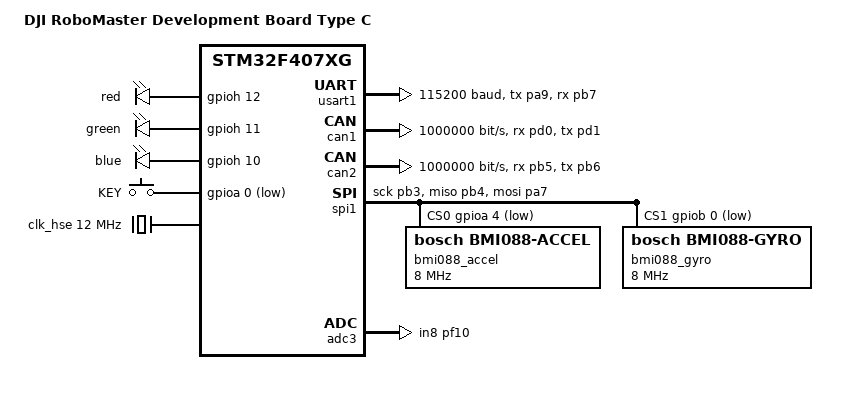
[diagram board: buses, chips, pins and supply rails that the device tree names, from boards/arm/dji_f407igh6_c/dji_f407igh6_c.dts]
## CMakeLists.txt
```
cmake_minimum_required(VERSION 3.20.0)

set(BOARD_ROOT ${CMAKE_CURRENT_SOURCE_DIR})

find_package(Zephyr REQUIRED HINTS $ENV{ZEPHYR_BASE})
project(zephyr_ascento_f407_wheel_leg C)

target_include_directories(app PRIVATE src)

target_sources(app PRIVATE
  src/main.c
  src/leds.c
  src/control_loop.c
  src/pid.c
  src/pid_balance_control.c
  src/ascento_balance.c
  src/dji_m3508.c
  src/dm4340.c
  src/motor_debug.c
  src/bmi088.c
  src/battery.c
  src/shell_commands.c
)

target_link_libraries(app PRIVATE m)
```

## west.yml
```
manifest:
  remotes:
    - name: zephyrproject-rtos
      url-base: https://github.com/zephyrproject-rtos
  projects:
    - name: zephyr
      remote: zephyrproject-rtos
      revision: v4.1.0
      import: true
  self:
    path: zephyr_ascento_f407_wheel_leg
```

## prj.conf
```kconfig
CONFIG_MAIN_STACK_SIZE=4096
CONFIG_SYSTEM_WORKQUEUE_STACK_SIZE=2048

CONFIG_GPIO=y
CONFIG_PINCTRL=y
CONFIG_SERIAL=y
CONFIG_CONSOLE=y
CONFIG_UART_CONSOLE=y
CONFIG_PRINTK=y

CONFIG_LOG=y
CONFIG_LOG_DEFAULT_LEVEL=3
CONFIG_LOG_MODE_IMMEDIATE=y

CONFIG_SHELL=y
CONFIG_KERNEL_SHELL=y
CONFIG_SHELL_STACK_SIZE=4096

CONFIG_CAN=y
CONFIG_SPI=y
CONFIG_ADC=y

CONFIG_FPU=y
CONFIG_NEWLIB_LIBC=y
CONFIG_NEWLIB_LIBC_FLOAT_PRINTF=y
CONFIG_CBPRINTF_FP_SUPPORT=y

CONFIG_THREAD_NAME=y
CONFIG_ASSERT=y

# Persistent parameter storage (direct flash read/write)
CONFIG_FLASH=y
CONFIG_FLASH_PAGE_LAYOUT=y
CONFIG_FLASH_MAP=y
CONFIG_CRC=y
```

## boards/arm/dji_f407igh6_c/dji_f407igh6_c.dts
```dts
/*
 * DJI RoboMaster Development Board Type C, STM32F407IGH6.
 *
 * The board exposes CAN1 on PD0/PD1 and CAN2 on PB5/PB6.
 * This robot uses CAN1 for DM43xx joint motors and CAN2 for DJI M3508 wheels.
 */

/dts-v1/;

#include <st/f4/stm32f407Xg.dtsi>
#include <zephyr/dt-bindings/gpio/gpio.h>
#include <zephyr/dt-bindings/pinctrl/stm32-pinctrl.h>
#include <zephyr/dt-bindings/input/input-event-codes.h>

/ {
	model = "DJI RoboMaster Development Board Type C";
	compatible = "dji,dji-f407igh6-c";

	chosen {
		zephyr,console = &usart1;
		zephyr,shell-uart = &usart1;
		zephyr,sram = &sram0;
		zephyr,flash = &flash0;
		zephyr,canbus = &can1;
	};

	aliases {
		led0 = &red_led;
		led1 = &green_led;
		led2 = &blue_led;
		sw0 = &key0;
		can-joint = &can1;
		can-dm = &can1;
		can-wheel = &can2;
		can-m3508 = &can2;
	};

	leds {
		compatible = "gpio-leds";

		red_led: red_led {
			gpios = <&gpioh 12 GPIO_ACTIVE_HIGH>;
			label = "red";
		};

		green_led: green_led {
			gpios = <&gpioh 11 GPIO_ACTIVE_HIGH>;
			label = "green";
		};

		blue_led: blue_led {
			gpios = <&gpioh 10 GPIO_ACTIVE_HIGH>;
			label = "blue";
		};
	};

	gpio_keys {
		compatible = "gpio-keys";

		key0: key_0 {
			gpios = <&gpioa 0 GPIO_ACTIVE_LOW>;
			label = "KEY";
			zephyr,code = <INPUT_KEY_0>;
		};
	};
};

&clk_hse {
	clock-frequency = <12000000>;
	status = "okay";
};

&pll {
	div-m = <12>;
	mul-n = <336>;
	div-p = <2>;
	div-q = <7>;
	clocks = <&clk_hse>;
	status = "okay";
};

&rcc {
	clocks = <&pll>;
	clock-frequency = <168000000>;
	ahb-prescaler = <1>;
	apb1-prescaler = <4>;
	apb2-prescaler = <2>;
};

&pinctrl {
	usart1_tx_pa9: usart1_tx_pa9 {
		pinmux = <STM32_PINMUX('A', 9, AF7)>;
	};

	usart1_rx_pb7: usart1_rx_pb7 {
		pinmux = <STM32_PINMUX('B', 7, AF7)>;
		bias-pull-up;
	};

	can1_rx_pd0: can1_rx_pd0 {
		pinmux = <STM32_PINMUX('D', 0, AF9)>;
		bias-pull-up;
	};

	can1_tx_pd1: can1_tx_pd1 {
		pinmux = <STM32_PINMUX('D', 1, AF9)>;
	};

	can2_rx_pb5: can2_rx_pb5 {
		pinmux = <STM32_PINMUX('B', 5, AF9)>;
		bias-pull-up;
	};

	can2_tx_pb6: can2_tx_pb6 {
		pinmux = <STM32_PINMUX('B', 6, AF9)>;
	};

	spi1_sck_pb3: spi1_sck_pb3 {
		pinmux = <STM32_PINMUX('B', 3, AF5)>;
	};

	spi1_miso_pb4: spi1_miso_pb4 {
		pinmux = <STM32_PINMUX('B', 4, AF5)>;
	};

	spi1_mosi_pa7: spi1_mosi_pa7 {
		pinmux = <STM32_PINMUX('A', 7, AF5)>;
	};

	adc3_in8_pf10: adc3_in8_pf10 {
		pinmux = <STM32_PINMUX('F', 10, ANALOG)>;
	};
};

&usart1 {
	pinctrl-0 = <&usart1_tx_pa9 &usart1_rx_pb7>;
	pinctrl-names = "default";
	current-speed = <115200>;
	status = "okay";
};

&can1 {
	pinctrl-0 = <&can1_rx_pd0 &can1_tx_pd1>;
	pinctrl-names = "default";
	bitrate = <1000000>;
	status = "okay";
};

&can2 {
	pinctrl-0 = <&can2_rx_pb5 &can2_tx_pb6>;
	pinctrl-names = "default";
	bitrate = <1000000>;
	status = "okay";
};

&spi1 {
	pinctrl-0 = <&spi1_sck_pb3 &spi1_miso_pb4 &spi1_mosi_pa7>;
	pinctrl-names = "default";
	cs-gpios = <&gpioa 4 GPIO_ACTIVE_LOW>, <&gpiob 0 GPIO_ACTIVE_LOW>;
	status = "okay";

	bmi088_accel: bmi088_accel@0 {
		compatible = "bosch,bmi088-accel";
		reg = <0>;
		spi-max-frequency = <8000000>;
	};

	bmi088_gyro: bmi088_gyro@1 {
		compatible = "bosch,bmi088-gyro";
		reg = <1>;
		spi-max-frequency = <8000000>;
	};
};

&adc3 {
	compatible = "st,stm32f4-adc", "st,stm32-adc";
	pinctrl-0 = <&adc3_in8_pf10>;
	pinctrl-names = "default";
	st,adc-prescaler = <2>;
	status = "okay";
};

/* Last 128 KB sector for NVS parameter storage. */
&flash0 {
	partitions {
		compatible = "fixed-partitions";
		#address-cells = <1>;
		#size-cells = <1>;

		storage_partition: partition@e0000 {
			label = "storage";
			reg = <0x0e0000 0x20000>;
		};
	};
};
```

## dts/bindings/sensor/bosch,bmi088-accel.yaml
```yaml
description: Bosch BMI088 accelerometer chip-select used by the application

compatible: "bosch,bmi088-accel"

include: spi-device.yaml
```

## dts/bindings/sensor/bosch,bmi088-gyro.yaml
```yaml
description: Bosch BMI088 gyroscope chip-select used by the application

compatible: "bosch,bmi088-gyro"

include: spi-device.yaml
```

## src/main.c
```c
/**
 * @file main.c
 * @brief Ascento 式双轮腿机器人 —— 系统入口与初始化
 *
 * 基于 Zephyr RTOS 的 STM32F407 双轮腿自平衡机器人主程序。
 *
 * 【硬件平台】
 *   - MCU: STM32F407 (DJI RoboMaster 开发板 C 型)
 *   - IMU: BMI088（SPI 接口，测量俯仰/横滚/偏航角及角速度）
 *   - 轮毂电机: DJI M3508 ×2（经 VESC 驱动器，CAN2 总线）
 *   - 关节电机: DM4340 ×2（髋关节直驱，CAN1 总线）
 *   - LED: 红/绿/蓝三色指示灯，用于状态反馈
 *
 * 【软件架构】
 *   - 主线程：外设初始化、LED 状态指示、500ms 周期日志输出
 *   - 控制线程：200Hz 实时平衡控制（见 control_loop.c）
 *
 * 【CAN 总线布局】
 *   - CAN1（joint）: DM4340 关节电机
 *   - CAN2（wheel）: DJI M3508 轮毂电机（VESC 协议）
 */

#include <errno.h>
#include <stdbool.h>
#include <stdint.h>

#include <zephyr/device.h>
#include <zephyr/devicetree.h>
#include <zephyr/drivers/can.h>
#include <zephyr/drivers/gpio.h>
#include <zephyr/kernel.h>
#include <zephyr/logging/log.h>
#include <zephyr/sys/util.h>

#include "app_config.h"
#include "battery.h"
#include "bmi088.h"
#include "control.h"
#include "control_loop.h"
#include "dji_m3508.h"
#include "dm4340.h"
#include "leds.h"
#include "motor_debug.h"

LOG_MODULE_REGISTER(app, LOG_LEVEL_INF);

/* ========== 设备树 CAN 节点别名 ========== */
#define WHEEL_CAN_NODE DT_ALIAS(can_wheel)
#define JOINT_CAN_NODE DT_ALIAS(can_joint)

/* ========== CAN 设备句柄 ========== */
static const struct device *wheel_can = DEVICE_DT_GET(WHEEL_CAN_NODE);
static const struct device *joint_can = DEVICE_DT_GET(JOINT_CAN_NODE);

/* ========== 电机和传感器全局对象 ========== */
static dji_m3508_bus_t dji_bus;
static dm4340_bus_t dm_bus;
static bmi088_t imu;

/* ========== 硬件初始化辅助函数 ========== */

/** @brief 初始化并启动指定 CAN 总线 */
static int prepare_can(const struct device *can, const char *name)
{
	if (!device_is_ready(can)) {
		LOG_ERR("%s is not ready", name);
		return -ENODEV;
	}

	int ret = can_set_bitrate(can, APP_CAN_BITRATE);
	if (ret != 0 && ret != -ENOTSUP) {
		LOG_WRN("%s bitrate set returned %d, using devicetree bitrate",
			name, ret);
	}

	ret = can_start(can);
	if (ret != 0 && ret != -EALREADY) {
		LOG_ERR("%s start failed: %d", name, ret);
		return ret;
	}

	LOG_INF("%s started at %u bps", name, APP_CAN_BITRATE);
	return 0;
}

/** @brief 检查是否有至少一台 DM4340 关节电机在线 */
static bool dm_any_online(void)
{
	for (uint8_t i = 1; i <= DM4340_MAX_ID; i++) {
		dm4340_feedback_t fb;
		if (dm4340_get(&dm_bus, i, &fb)) {
			return true;
		}
	}
	return false;
}

/* ========== 主函数 ========== */

int main(void)
{
	LOG_INF("DJI F407 Ascento wheel-leg Zephyr app boot");

	/* ===== 阶段 1：硬件外设初始化 ===== */
	leds_init();

	/* CAN 总线初始化 */
	if (prepare_can(joint_can, "CAN joint DM43xx") != 0) {
		LOG_ERR("joint CAN is required");
	}
	if (joint_can != wheel_can) {
		if (prepare_can(wheel_can, "CAN wheel VESC") != 0) {
			LOG_ERR("wheel CAN is required");
		}
	}

	/* 电机驱动初始化 */
	const uint8_t wheel_ids[] = { APP_WHEEL_LEFT_ID, APP_WHEEL_RIGHT_ID };
	(void)dji_m3508_init(&dji_bus, wheel_can, wheel_ids,
			     ARRAY_SIZE(wheel_ids));
	(void)dm4340_init(&dm_bus, joint_can, APP_DM_LEFT_FEEDBACK_ID,
			  APP_DM_RIGHT_FEEDBACK_ID);
	motor_debug_init(&dji_bus, &dm_bus);
	(void)dm4340_enable(&dm_bus, APP_DM_LEFT_ID);
	(void)dm4340_enable(&dm_bus, APP_DM_RIGHT_ID);

	/* 传感器初始化 */
	if (bmi088_init(&imu) != 0) {
		LOG_ERR("BMI088 init failed; balance output will stay disabled");
	}
	(void)battery_init();

	/* ===== 阶段 2：启动实时控制线程（200Hz） ===== */
	control_loop_start(&dji_bus, &dm_bus, &imu);

	/* ===== 阶段 3：主线程监控循环（500ms） ===== */
	bool heartbeat = false;
	while (true) {
		heartbeat = !heartbeat;

		control_status_t status;
		control_get_status(&status);

		const battery_sample_t battery = battery_read();

		/* LED 状态指示 */
		led_set_red(!dm_any_online() || status.faulted ||
			    !status.wheels_enabled);
		led_set_blue(battery.valid &&
			     battery.voltage_v > APP_BATTERY_LED_THRESHOLD_V);

		/* 周期日志输出 */
		if (battery.valid) {
			LOG_INF("pitch %.2f roll %.2f yaw %.1f gy %.1f gz %.1f current %d/%d "
				"height %d batt %.2f V",
				(double)status.pitch_deg,
				(double)status.roll_deg,
				(double)status.yaw_deg,
				(double)last_imu_sample.gy_dps,
				(double)last_imu_sample.gz_dps,
				status.left_wheel_current,
				status.right_wheel_current, status.height,
				(double)battery.voltage_v);
		} else {
			LOG_INF("pitch %.2f roll %.2f yaw %.1f gy %.1f gz %.1f current %d/%d "
				"height %d",
				(double)status.pitch_deg,
				(double)status.roll_deg,
				(double)status.yaw_deg,
				(double)last_imu_sample.gy_dps,
				(double)last_imu_sample.gz_dps,
				status.left_wheel_current,
				status.right_wheel_current, status.height);
		}

		k_sleep(K_MSEC(500));
	}
}
```

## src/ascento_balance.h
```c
/**
 * @file ascento_balance.h
 * @brief Ascento 风格轮腿机器人的模型化平衡控制器
 *
 * 本文件实现了基于物理模型的平衡控制器，核心思路源自 Ascento 机器人。
 * 控制器使用 LQR（线性二次调节器）方法，基于机器人的物理参数
 * （质量、惯量、轮半径、腿长等）计算最优反馈增益。
 *
 * 工作原理：
 *   1. 将机器人建模为倒立摆 + 轮子系统（5 个状态变量）
 *   2. 根据当前腿部长度动态计算 LQR 增益（增益随腿长变化）
 *   3. 增益通过多项式拟合（c0, c1, c2, c3）预计算，运行时查表
 *   4. 输出轮子扭矩指令，实现自平衡 + 前进/转向控制
 *   5. 包含静摩擦补偿、故障保护、偏航同步等功能
 *
 * 参数存储：
 *   - 默认参数通过 #define 宏定义（编译时确定）
 *   - 运行时可通过 NVS（非易失性存储）持久化自定义参数
 *   - ascento_balance_save_params() / reset_params() 管理持久化
 */

#pragma once

#include <stdbool.h>
#include <stdint.h>

#include "bmi088.h"   /* IMU 传感器数据类型 */
#include "dji_m3508.h" /* DJI M3508 电机数据类型 */

/**
 * @brief Ascento 平衡控制器参数结构体
 *
 * 包含机器人的物理参数、LQR 增益、运行时可调参数等。
 * 物理参数在初始化时设定，运行时通常不变；
 * LQR 增益和保护阈值可在运行时调整。
 */
typedef struct {
	bool calibrated; /**< 是否已完成校准（true = 参数有效） */

	/* ========== 机器人物理参数（几何与质量） ========== */

	float wheel_radius_m;    /**< 轮子半径，单位：米（m） */
	float wheel_base_m;      /**< 左右轮距（轮距），单位：米（m） */
	float total_mass_kg;     /**< 机器人总质量，单位：千克（kg） */
	float body_com_height_m; /**< 质心高度（从轮轴到质心的距离），单位：米（m） */
	float body_com_forward_offset_m; /**< 质心前后偏移（正=前倾方向），单位：米（m） */

	/* ========== 转动惯量参数 ========== */

	float body_pitch_inertia_kg_m2; /**< 机体绕俯仰轴的转动惯量，单位：kg*m^2 */
	float wheel_inertia_kg_m2;      /**< 轮子绕转轴的转动惯量，单位：kg*m^2 */

	/* ========== 电机电流到扭矩的转换系数 ========== */

	float current_ma_to_wheel_torque_nm;           /**< 默认电流-扭矩转换系数，单位：N*m/mA */
	float left_current_ma_to_wheel_torque_nm;  /**< 左轮专用电流-扭矩系数（补偿个体差异），单位：N*m/mA */
	float right_current_ma_to_wheel_torque_nm; /**< 右轮专用电流-扭矩系数（补偿个体差异），单位：N*m/mA */

	/* ========== 腿部几何参数（关节角度 <-> 腿长映射） ========== */

	float leg_length_min_m;     /**< 腿部最短长度，单位：米（m） */
	float leg_length_max_m;     /**< 腿部最长长度，单位：米（m） */
	float leg_length_default_m; /**< 腿部默认长度（初始站立高度），单位：米（m） */

	/* 关节角度与腿长的对应关系（用于关节角 -> 腿长的线性映射） */
	float left_joint_at_min_leg_rad;  /**< 左腿在最短腿长时的关节角度，单位：弧度（rad） */
	float left_joint_at_max_leg_rad;  /**< 左腿在最长腿长时的关节角度，单位：弧度（rad） */
	float right_joint_at_min_leg_rad; /**< 右腿在最短腿长时的关节角度，单位：弧度（rad） */
	float right_joint_at_max_leg_rad; /**< 右腿在最长腿长时的关节角度，单位：弧度（rad） */

	/* ========== LQR 状态反馈增益（固定部分） ========== */

	float k_pitch;     /**< 俯仰角反馈增益（平衡主回路），单位：N*m/rad */
	float k_pitch_rate; /**< 俯仰角速度反馈增益（阻尼），单位：N*m/(rad/s) */
	float k_position;  /**< 位置反馈增益（防止位置漂移），单位：N*m/m */
	float k_velocity;  /**< 速度反馈增益（速度阻尼），单位：N*m/(m/s) */
	float k_yaw_rate;  /**< 偏航角速度反馈增益（转向阻尼），单位：N*m/(rad/s) */
	float k_roll_to_leg_m_per_rad; /**< 横滚角到腿部差动的映射系数，单位：m/rad */

	/* ========== 运行时可调参数（可从 #define 默认值覆盖） ========== */

	float theta_eq_rad; /**< 平衡点俯仰角偏移（站立时的"零点"），单位：弧度（rad） */

	/* 以下 gain_c*_a/b/c 为腿部长度 -> LQR 增益的多项式拟合系数 */
	/* 用于动态计算：gain = a * leg_len^2 + b * leg_len + c */
	float gain_c0_a, gain_c0_b, gain_c0_c;  /**< 增益 c0 的多项式系数（遗留/Flash 兼容） */
	float gain_c1_a, gain_c1_b, gain_c1_c;  /**< 增益 c1 的多项式系数（遗留/Flash 兼容） */
	float gain_c2;                           /**< 增益 c2 的常数值（遗留/Flash 兼容） */
	float gain_c3_a, gain_c3_b, gain_c3_c;  /**< 增益 c3 的多项式系数（遗留/Flash 兼容） */

	/* ========== 静摩擦补偿参数 ========== */

	float stiction_current_ma;  /**< 最大静摩擦补偿电流，单位：毫安（mA） */
	float stiction_start_deg;   /**< 开始施加静摩擦补偿的角度阈值，单位：度（deg） */
	float stiction_full_deg;    /**< 施加满静摩擦补偿的角度阈值，单位：度（deg） */

	/* ========== 保护与限幅参数 ========== */

	int16_t current_limit_ma;   /**< 轮子最大输出电流限幅，单位：毫安（mA） */
	float current_scale;        /**< 电流输出缩放系数（0.0~1.0，用于降功率运行） */
	float fault_deg;            /**< 触发故障保护的倾角阈值，单位：度（deg） */
	float recover_deg;          /**< 从故障状态恢复的角度阈值（需低于 fault_deg），单位：度（deg） */

	/* ========== 偏航同步参数 ========== */

	float wheel_sync_gain_ma;          /**< 左右轮差速同步增益，单位：mA/(rad/s) */
	float wheel_sync_current_limit_ma; /**< 差速同步最大电流限幅，单位：毫安（mA） */
} ascento_balance_params_t;

/**
 * @brief Ascento 平衡控制器输入结构体
 *
 * 每个控制周期由调用方填充，包含传感器反馈和运动目标。
 */
typedef struct {
	bool enable_request;     /**< 控制器使能请求（false 时输出为零） */
	bool wheel_feedback_ok;  /**< 轮子电机反馈是否有效（通信正常） */
	float dt_s;              /**< 本控制周期的时间步长，单位：秒（s） */

	/* 运动目标 */
	float target_forward_speed_mps; /**< 目标前进速度，单位：米/秒（m/s），正值=前进 */
	float target_yaw_rate_rad_s;    /**< 目标偏航角速度，单位：弧度/秒（rad/s），正值=右转 */
	float target_pitch_rad;         /**< 目标俯仰角（通常为零，用于特殊姿态），单位：弧度（rad） */

	/* 关节反馈（来自腿部关节电机编码器） */
	float left_joint_position_rad;  /**< 左腿关节当前角度，单位：弧度（rad） */
	float right_joint_position_rad; /**< 右腿关节当前角度，单位：弧度（rad） */
	float left_joint_velocity_rad_s;  /**< 左腿关节角速度，单位：弧度/秒（rad/s） */
	float right_joint_velocity_rad_s; /**< 右腿关节角速度，单位：弧度/秒（rad/s） */

	/* 传感器反馈 */
	bmi088_sample_t imu;         /**< IMU 采样数据（加速度、角速度、姿态角） */
	dji_m3508_motor_t left_wheel;  /**< 左轮电机反馈（电流、角度、速度） */
	dji_m3508_motor_t right_wheel; /**< 右轮电机反馈（电流、角度、速度） */
} ascento_balance_input_t;

/**
 * @brief Ascento 平衡控制器输出结构体
 *
 * 每个控制周期由 ascento_balance_update() 填充，包含电机指令和内部状态。
 */
typedef struct {
	bool active;       /**< 控制器是否处于活跃状态（已使能且未故障） */
	bool params_ready; /**< 参数是否已就绪（已加载有效参数） */
	bool faulted;      /**< 是否处于故障保护状态 */

	/* 电机输出指令 */
	int16_t left_wheel_current;  /**< 左轮目标电流，单位：毫安（mA） */
	int16_t right_wheel_current; /**< 右轮目标电流，单位：毫安（mA） */
	float left_joint_position_rad;  /**< 左腿关节目标角度，单位：弧度（rad） */
	float right_joint_position_rad; /**< 右腿关节目标角度，单位：弧度（rad） */
	float joint_velocity_limit_rad_s; /**< 关节角速度限幅，单位：弧度/秒（rad/s） */

	/* 内部计算中间量（用于调试和监控） */
	float body_position_m;   /**< 机体估计位置（轮子编码器积分），单位：米（m） */
	float body_velocity_mps; /**< 机体估计速度（编码器微分 + 滤波），单位：米/秒（m/s） */
	float pitch_rad;         /**< 机体俯仰角（IMU 融合后），单位：弧度（rad） */
	float pitch_rate_rad_s;  /**< 机体俯仰角速度（陀螺仪），单位：弧度/秒（rad/s） */
	float balance_torque_nm; /**< 平衡控制计算的总扭矩，单位：牛顿米（N*m） */
	float yaw_torque_nm;     /**< 偏航控制计算的差动扭矩，单位：牛顿米（N*m） */
} ascento_balance_output_t;

/**
 * @brief Ascento 平衡控制器内部状态结构体
 *
 * 保存控制器的持久化运行状态（跨控制周期保持）。
 * 由 ascento_balance_init() 初始化，ascento_balance_update() 更新。
 */
typedef struct {
	bool initialized;  /**< 控制器是否已初始化 */
	bool faulted;      /**< 是否处于故障保护状态 */
	int recover_ticks; /**< 故障恢复倒计时（tick 数，降到零后尝试恢复平衡） */

	float body_position_m;        /**< 机体累计位移估计，单位：米（m） */
	float wheel_position_zero_m;  /**< 轮子位置零点偏移（用于位置估计归零），单位：米（m） */
	float body_velocity_lpf_mps;  /**< 机体速度的低通滤波值，单位：米/秒（m/s） */
	float yaw_rate_lpf_rad_s;     /**< 偏航角速度的低通滤波值，单位：弧度/秒（rad/s） */
	float pitch_rate_lpf_rad_s;   /**< 俯仰角速度的低通滤波值，单位：弧度/秒（rad/s） */
} ascento_balance_state_t;

/**
 * @brief 默认参数指针（指向编译时定义的默认参数表）
 *
 * 可用于在 NVS 参数损坏时恢复出厂默认值。
 */
extern const ascento_balance_params_t *ascento_balance_default_params;

/**
 * @brief 获取当前平衡控制器参数
 * @param[out] params 指向参数结构体的指针，函数将填充当前参数值
 */
void ascento_balance_get_params(ascento_balance_params_t *params);

/**
 * @brief 设置平衡控制器参数
 * @param[in] params 指向新参数结构体的指针
 *
 * 运行时动态更新参数（不持久化到 Flash）。
 */
void ascento_balance_set_params(const ascento_balance_params_t *params);

/**
 * @brief 将当前参数持久化保存到 NVS（Flash）
 * @return 0 成功，非零失败
 */
int ascento_balance_save_params(void);

/**
 * @brief 将参数重置为出厂默认值
 * @return 0 成功，非零失败
 *
 * 从 NVS 中擦除自定义参数，恢复为 #define 编译时默认值。
 */
int ascento_balance_reset_params(void);

/**
 * @brief 初始化平衡控制器的 NVS 参数存储
 * @return 0 成功，非零失败
 *
 * 从 NVS 加载已保存的参数；若 NVS 为空则使用默认值。
 * 应在系统启动时调用一次。
 */
int ascento_balance_settings_init(void);

/**
 * @brief 初始化平衡控制器状态
 * @param[out] state 指向控制器状态结构体的指针
 *
 * 清零所有内部状态，设置 initialized 标志。
 */
void ascento_balance_init(ascento_balance_state_t *state);

/**
 * @brief 重置平衡控制器状态
 * @param[out] state 指向控制器状态结构体的指针
 *
 * 重置位置估计、滤波器状态等，但保留初始化标志。
 * 用于从故障状态恢复或重新站立时调用。
 */
void ascento_balance_reset(ascento_balance_state_t *state);

/**
 * @brief 检查参数是否已就绪
 * @param[in] params 指向参数结构体的指针
 * @return true = 参数有效（已校准且值合理），false = 参数无效
 */
bool ascento_balance_params_ready(const ascento_balance_params_t *params);

/**
 * @brief 根据关节角度计算腿部长度
 * @param[in] params    指向参数结构体的指针（需要关节-腿长映射参数）
 * @param[in] left_leg  true = 左腿，false = 右腿
 * @param[in] joint_rad 关节角度，单位：弧度（rad）
 * @return 腿部长度，单位：米（m）
 *
 * 使用线性插值将关节角度映射到腿部长度。
 */
float ascento_balance_leg_length_from_joint(const ascento_balance_params_t *params,
					    bool left_leg, float joint_rad);

/**
 * @brief 平衡控制器主更新函数（每个控制周期调用一次）
 * @param[in,out] state  控制器内部状态（跨周期保持）
 * @param[in]     params 控制器参数（物理参数 + 增益）
 * @param[in]     input  本周期的传感器反馈和运动目标
 * @param[out]    output 本周期的电机输出指令和中间量
 *
 * 执行完整的平衡控制算法：
 *   1. 从关节角度计算当前腿长
 *   2. 根据腿长计算 LQR 增益（多项式拟合）
 *   3. 计算 5 维状态向量：[俯仰角, 俯仰角速度, 位置, 速度, 偏航角速度]
 *   4. LQR 状态反馈计算平衡扭矩
 *   5. 叠加静摩擦补偿和偏航控制
 *   6. 电流限幅后输出轮子电流指令
 *   7. 计算关节目标角度（根据目标高度）
 *   8. 故障检测与保护
 */
void ascento_balance_update(ascento_balance_state_t *state,
			    const ascento_balance_params_t *params,
			    const ascento_balance_input_t *input,
			    ascento_balance_output_t *output);
```

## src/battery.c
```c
/**
 * @file battery.c
 * @brief 电池电压 ADC 采样模块
 *
 * 本文件通过 STM32F407 的 ADC3 外设读取电池电压。
 * 电池电压经过外部电阻分压后接入 ADC 输入引脚，本模块负责：
 *   1. 初始化 ADC 通道（配置增益、参考电压、采样时间等）
 *   2. 执行单次 ADC 转换，获取原始采样值
 *   3. 将原始 ADC 值转换为实际电压值（考虑分压比）
 *
 * 读取到的电池电压用于主循环中的状态指示（LED 显示）和日志输出，
 * 以便操作人员实时监控电池电量，防止电池过放。
 */

#include "battery.h"

#include "app_config.h"

#include <errno.h>
#include <stdint.h>

#include <zephyr/device.h>
#include <zephyr/drivers/adc.h>
#include <zephyr/logging/log.h>
#include <zephyr/sys/util.h>

/* 注册电池模块的日志标签为 "battery"，默认日志级别为 INFO */
LOG_MODULE_REGISTER(battery, LOG_LEVEL_INF);

/* 从设备树中获取 ADC3 外设节点，用于电池电压采集 */
#define BATTERY_ADC_NODE DT_NODELABEL(adc3)

/* ADC3 设备句柄，通过设备树宏在编译时绑定 */
static const struct device *adc_dev = DEVICE_DT_GET(BATTERY_ADC_NODE);

/* ADC 采样结果缓冲区，存放 12 位 ADC 原始值（有符号 16 位整数） */
static int16_t adc_sample;

/**
 * @brief 初始化电池 ADC 采集模块
 *
 * 检查 ADC3 设备是否就绪，然后配置 ADC 通道参数：
 *   - 增益：1 倍（无放大）
 *   - 参考电压：内部参考电压
 *   - 采样时间：默认值
 *   - 通道号：由 app_config.h 中 APP_BATTERY_ADC_CHANNEL 指定
 *
 * @return 0 表示初始化成功；-ENODEV 表示 ADC 设备未就绪；其他负值表示通道配置失败
 */
int battery_init(void)
{
	/* 检查 ADC3 设备是否已就绪（设备树中是否正确配置并初始化） */
	if (!device_is_ready(adc_dev)) {
		LOG_WRN("ADC3 is not ready; battery reading disabled");
		return -ENODEV;
	}

	/* 配置 ADC 通道参数 */
	const struct adc_channel_cfg channel_cfg = {
		.gain = ADC_GAIN_1,              /* 增益为 1，不进行信号放大 */
		.reference = ADC_REF_INTERNAL,    /* 使用 MCU 内部参考电压 */
		.acquisition_time = ADC_ACQ_TIME_DEFAULT, /* 采样保持时间使用默认值 */
		.channel_id = APP_BATTERY_ADC_CHANNEL,    /* ADC 通道编号，由配置文件定义 */
	};

	/* 调用 Zephyr ADC API 设置通道，返回 0 表示成功 */
	const int ret = adc_channel_setup(adc_dev, &channel_cfg);
	if (ret != 0) {
		LOG_WRN("ADC channel setup failed: %d", ret);
		return ret;
	}

	LOG_INF("battery ADC ready");
	return 0;
}

/**
 * @brief 执行一次电池电压 ADC 采样并返回电压值
 *
 * 执行流程：
 *   1. 检查 ADC 设备是否就绪
 *   2. 配置 ADC 转换序列（通道、缓冲区、分辨率）
 *   3. 执行 ADC 读取，获取 12 位原始采样值
 *   4. 将原始值转换为毫伏值：adc_mv = raw * full_scale_mv / 4095
 *   5. 再根据外部电阻分压比转换为实际电池电压：voltage = adc_mv * divider_ratio / 1000
 *
 * @return battery_sample_t 结构体，包含：
 *   - valid: true 表示采样成功，false 表示采样失败
 *   - voltage_v: 实际电池电压（单位：伏特），失败时为 0.0f
 */
battery_sample_t battery_read(void)
{
	/* 默认返回无效采样结果（valid=false, voltage=0V） */
	battery_sample_t sample = {
		.valid = false,
		.voltage_v = 0.0f,
	};

	/* 如果 ADC 设备未就绪，直接返回无效结果 */
	if (!device_is_ready(adc_dev)) {
		return sample;
	}

	/* 配置 ADC 转换序列 */
	struct adc_sequence sequence = {
		.channels = BIT(APP_BATTERY_ADC_CHANNEL),  /* 指定要采集的通道（位掩码） */
		.buffer = &adc_sample,            /* 采样结果存放的缓冲区指针 */
		.buffer_size = sizeof(adc_sample), /* 缓冲区大小（2 字节，对应 int16_t） */
		.resolution = 12,                 /* ADC 分辨率为 12 位（0~4095） */
	};

	/* 执行 ADC 单次转换读取 */
	const int ret = adc_read(adc_dev, &sequence);
	if (ret != 0) {
		return sample;  /* 读取失败，返回无效结果 */
	}

	/*
	 * ADC 原始值到实际电压的转换：
	 *   1. 先将 12 位 ADC 值（0~4095）映射到 0~FULL_SCALE_MV 毫伏范围
	 *   2. 再乘以分压比（divider_ratio），还原电池端实际电压
	 *   3. 最后除以 1000 将毫伏转换为伏特
	 *
	 * 例如：若 FULL_SCALE_MV=3300, DIVIDER_RATIO=11.0, adc_sample=2048
	 *   adc_mv = 2048 * 3300 / 4095 = 1651.5 mV
	 *   voltage = 1651.5 * 11.0 / 1000 = 18.17 V
	 */
	const float adc_mv = ((float)adc_sample * APP_BATTERY_ADC_FULL_SCALE_MV) /
			     4095.0f;
	sample.voltage_v = adc_mv * APP_BATTERY_DIVIDER_RATIO / 1000.0f;
	sample.valid = true;  /* 标记采样成功 */
	return sample;
}
```

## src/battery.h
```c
/**
 * @file battery.h
 * @brief 电池电压读取模块
 *
 * 本文件提供电池电压的 ADC 采集接口。
 * 用于监控电池电量，当电压过低时可触发低电量保护
 * （如降低功率输出或报警）。
 *
 * 硬件说明：
 *   - 通常使用 STM32 内置 ADC 采集电池电压
 *   - 电池电压经过分压电阻后接入 ADC 引脚
 *   - 软件中根据分压比和 ADC 参考电压换算实际电压
 */

#pragma once

#include <stdbool.h>

/**
 * @brief 电池采样数据结构体
 */
typedef struct {
	float voltage_v; /**< 电池电压，单位：伏特（V） */
	bool valid;      /**< 采样是否有效（true = ADC 读取成功，false = 读取失败/未初始化） */
} battery_sample_t;

/**
 * @brief 初始化电池电压采集模块
 * @return 0 成功，非零失败
 *
 * 配置 ADC 外设和相关 GPIO 引脚。
 * 应在系统启动时调用一次。
 */
int battery_init(void);

/**
 * @brief 读取当前电池电压
 * @return battery_sample_t 结构体，包含电压值和有效性标志
 *
 * 每次调用执行一次 ADC 采样并转换为实际电压值。
 * 典型调用频率：1~10 Hz（电池电压变化缓慢，无需高频采样）。
 */
battery_sample_t battery_read(void);
```

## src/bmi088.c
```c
/**
 * @file bmi088.c
 * @brief BMI088 六轴惯性测量单元（IMU）SPI驱动及姿态解算模块
 *
 * 本文件实现了 Bosch BMI088 六轴 IMU 的驱动程序，包含：
 *   1. 通过 SPI 总线读写加速度计和陀螺仪寄存器
 *   2. 原始传感器数据的读取和单位换算
 *   3. 陀螺仪零偏校准（上电静止时采集300个样本取均值）
 *   4. 基于互补滤波器的姿态估计（横滚角roll、俯仰角pitch、偏航角yaw）
 *
 * BMI088 芯片特性：
 *   - 加速度计：三轴加速度，量程 ±6g，灵敏度 5460 LSB/g
 *   - 陀螺仪：三轴角速度，量程 ±2000°/s，灵敏度 16.384 LSB/(°/s)
 *   - 加速度计和陀螺仪各自拥有独立的 SPI 片选线
 *
 * 坐标轴重映射说明：
 *   在本机器人PCB上，BMI088芯片的X轴指向机器人侧向（即机器人的横滚轴roll），
 *   芯片Y轴指向前方（即机器人的俯仰轴pitch）。因此在姿态解算时需要进行轴映射：
 *     - 机器人roll  <- 加速度计X轴 / 陀螺仪Y轴
 *     - 机器人pitch <- 加速度计Y轴 / 陀螺仪X轴
 */

#include "bmi088.h"

#include <errno.h>
#include <math.h>
#include <string.h>

#include <zephyr/kernel.h>
#include <zephyr/logging/log.h>
#include <zephyr/sys/util.h>

#include "app_config.h"

LOG_MODULE_REGISTER(bmi088, LOG_LEVEL_INF);

/* =========================================================================
 * 设备树节点标签 —— 对应 DTS 中定义的加速度计和陀螺仪 SPI 设备
 * BMI088 的加速度计和陀螺仪是独立的 SPI 从设备，各有各的片选线
 * ========================================================================= */
#define BMI088_ACCEL_NODE DT_NODELABEL(bmi088_accel)
#define BMI088_GYRO_NODE  DT_NODELABEL(bmi088_gyro)

/* =========================================================================
 * BMI088 加速度计寄存器地址（参考 BMI088 数据手册第 7 节 Register Map）
 * 加速度计使用 8 位寄存器地址，SPI 读操作时需将最高位置 1（或 0x80）
 * ========================================================================= */
#define BMI088_ACCEL_CHIP_ID   0x00  /* 芯片 ID 寄存器，读取值应为 0x1E */
#define BMI088_ACCEL_DATA      0x12  /* 加速度数据起始寄存器，6 字节连续读取：
                                       [0x12-0x13] X 轴, [0x14-0x15] Y 轴,
                                       [0x16-0x17] Z 轴，小端格式 int16 */
#define BMI088_ACCEL_CONF      0x40  /* 加速度计配置寄存器：设置 ODR（输出数据速率）
                                       和带宽（BWP），写入 0xA8 表示 ODR=800Hz,
                                       BWP=OSR4（过采样率4倍） */
#define BMI088_ACCEL_RANGE     0x41  /* 加速度计量程寄存器，写入 0x01 = ±6g */
#define BMI088_ACCEL_PWR_CONF  0x7c  /* 电源模式配置寄存器，写入 0x00 = active 模式 */
#define BMI088_ACCEL_PWR_CTRL  0x7d  /* 电源控制寄存器，写入 0x04 = 开启加速度计 */
#define BMI088_ACCEL_SOFTRESET 0x7e  /* 软复位寄存器，写入 0xB6 执行复位 */

/* =========================================================================
 * BMI088 陀螺仪寄存器地址（参考 BMI088 数据手册第 8 节 Register Map）
 * 陀螺仪使用 8 位寄存器地址，SPI 读操作时地址无需置位（直接发送原地址）
 * ========================================================================= */
#define BMI088_GYRO_CHIP_ID    0x00  /* 芯片 ID 寄存器，读取值应为 0x0F */
#define BMI088_GYRO_DATA       0x02  /* 陀螺仪数据起始寄存器，6 字节连续读取：
                                       [0x02-0x03] X 轴, [0x04-0x05] Y 轴,
                                       [0x06-0x07] Z 轴，小端格式 int16 */
#define BMI088_GYRO_RANGE      0x0f  /* 陀螺仪量程寄存器，写入 0x00 = ±2000°/s */
#define BMI088_GYRO_BANDWIDTH  0x10  /* 陀螺仪带宽/ODR 寄存器，写入 0x02 =
                                       ODR=1000Hz, 带宽=116Hz (滤波器截止频率) */
#define BMI088_GYRO_LPM1       0x11  /* 低功耗模式寄存器，写入 0x00 = 正常模式 */
#define BMI088_GYRO_SOFTRESET  0x14  /* 软复位寄存器，写入 0xB6 执行复位 */

/* =========================================================================
 * 芯片 ID 校验值 —— 用于初始化时验证 SPI 通信是否正常
 * 读取 CHIP_ID 寄存器并与以下常量比对
 * ========================================================================= */
#define BMI088_ACCEL_ID_VALUE  0x1e  /* 加速度计芯片 ID 固定值 */
#define BMI088_GYRO_ID_VALUE   0x0f  /* 陀螺仪芯片 ID 固定值 */

/* =========================================================================
 * 换算常量 —— 将原始 ADC 计数值转换为物理单位
 * 当量程为 ±6g 时：灵敏度 = 5460 LSB/g
 * 当量程为 ±2000°/s 时：灵敏度 = 16.384 LSB/(°/s)
 * 原始值除以这些常量即得到 g 或 °/s 为单位的物理量
 * ========================================================================= */
#define BMI088_ACCEL_LSB_PER_G   5460.0f
#define BMI088_GYRO_LSB_PER_DPS  16.384f

/**
 * @brief 获取当前系统时间（微秒精度）
 *
 * 使用 Zephyr 内核的硬件时钟周期计数器，转换为微秒时间戳。
 * 用于互补滤波器中计算两次采样之间的时间间隔 dt。
 *
 * @return 当前时间，单位为微秒（us）
 */
static int64_t now_us(void)
{
	return k_cyc_to_us_floor64(k_cycle_get_64());
}

/**
 * @brief 通过 SPI 读取 BMI088 的一个或多个连续寄存器
 *
 * BMI088 SPI 读操作协议（详见数据手册 Section 4.2.2）：
 *
 * 【加速度计】SPI 读时序：
 *   MOSI: [寄存器地址 | 0x80] [Dummy字节] [Dummy...] ...
 *   MISO: [无效]              [Dummy字节] [数据0] [数据1] ...
 *   说明：加速度计在读操作时，地址字节后需要插入一个 Dummy 字节（无意义），
 *         随后的 MISO 字节才是有效数据。因此 dummy = 1。
 *
 * 【陀螺仪】SPI 读时序：
 *   MOSI: [寄存器地址 | 0x80] [Dummy...] ...
 *   MISO: [无效]              [数据0] [数据1] ...
 *   说明：陀螺仪读操作时，地址字节后直接返回数据，无 Dummy 字节。因此 dummy = 0。
 *
 * 两者共同点：读操作时寄存器地址最高位需置 1（即 reg | 0x80），
 *             数据以小端（Little-Endian）格式传输。
 *
 * @param spi   SPI 设备规格（加速度计或陀螺仪）
 * @param reg   起始寄存器地址
 * @param data  输出缓冲区，存放读取到的数据
 * @param len   要读取的字节数
 * @param accel 是否为加速度计（true = 加速度计，需要 Dummy 字节；false = 陀螺仪）
 * @return 0 成功，负数表示 SPI 传输失败
 */
static int spi_read_reg(const struct spi_dt_spec *spi, uint8_t reg,
			uint8_t *data, size_t len, bool accel)
{
	uint8_t tx[12] = { 0 };
	uint8_t rx[12] = { 0 };
	/* 加速度计读操作需要 1 个 Dummy 字节，陀螺仪不需要 */
	const size_t dummy = accel ? 1U : 0U;
	/* 总传输长度 = 1字节地址 + dummy字节 + 数据字节数 */
	const size_t total = 1U + dummy + len;

	/* 安全检查：确保传输长度不超过缓冲区大小 */
	if (total > sizeof(tx)) {
		return -EINVAL;
	}

	/* 构造地址字节：最高位置 1 表示读操作 */
	tx[0] = reg | 0x80U;

	const struct spi_buf tx_buf = {
		.buf = tx,
		.len = total,
	};
	const struct spi_buf rx_buf = {
		.buf = rx,
		.len = total,
	};
	const struct spi_buf_set tx_set = {
		.buffers = &tx_buf,
		.count = 1,
	};
	const struct spi_buf_set rx_set = {
		.buffers = &rx_buf,
		.count = 1,
	};

	/* 执行 SPI 全双工收发：同时发送地址和接收数据 */
	const int ret = spi_transceive_dt(spi, &tx_set, &rx_set);
	if (ret == 0) {
		/* 从接收缓冲区中提取有效数据：
		 * rx[0] 是地址字节的响应（无效），跳过；
		 * rx[1] 对于加速度计是 Dummy 字节，对于陀螺仪已是第一个数据字节；
		 * 有效数据从 rx[1 + dummy] 开始 */
		memcpy(data, &rx[1U + dummy], len);
	}
	return ret;
}

/**
 * @brief 通过 SPI 向 BMI088 写入单个寄存器
 *
 * BMI088 SPI 写操作协议：
 *   MOSI: [寄存器地址 & 0x7F] [数据字节]
 *   写操作时，寄存器地址最高位必须为 0（即 reg & 0x7F），
 *   第二个字节为要写入的数据值。整个操作仅需 2 字节。
 *
 * @param spi   SPI 设备规格（加速度计或陀螺仪）
 * @param reg   目标寄存器地址
 * @param value 要写入的值
 * @return 0 成功，负数表示 SPI 传输失败
 */
static int spi_write_reg(const struct spi_dt_spec *spi, uint8_t reg,
			 uint8_t value)
{
	/* 地址字节最高位清零表示写操作 */
	uint8_t tx[2] = { reg & 0x7fU, value };
	const struct spi_buf tx_buf = {
		.buf = tx,
		.len = sizeof(tx),
	};
	const struct spi_buf_set tx_set = {
		.buffers = &tx_buf,
		.count = 1,
	};

	return spi_write_dt(spi, &tx_set);
}

/**
 * @brief 将两个字节按小端序（Little-Endian）组合为有符号 16 位整数
 *
 * BMI088 的传感器数据寄存器采用小端格式存储：
 *   data[0] = 低字节（LSB），data[1] = 高字节（MSB）
 * 组合后解释为有符号整数（int16），范围 -32768 ~ +32767。
 *
 * @param data 指向两个字节的指针
 * @return 组合后的 int16 值
 */
static int16_t le_i16(const uint8_t *data)
{
	return (int16_t)((uint16_t)data[1] << 8 | data[0]);
}

/**
 * @brief 从 BMI088 读取一次完整的原始传感器数据并转换为物理单位
 *
 * 执行流程：
 *   1. 从加速度计连续读取 6 字节数据（X/Y/Z 各 2 字节，小端 int16）
 *   2. 将原始 ADC 值除以灵敏度（5460 LSB/g）换算为重力加速度 g
 *   3. 从陀螺仪连续读取 6 字节数据
 *   4. 将原始 ADC 值除以灵敏度（16.384 LSB/°/s）换算为角速度 °/s
 *   5. 减去陀螺仪零偏校准值，得到校准后的角速度
 *
 * @param imu    BMI088 设备实例
 * @param sample 输出结构体，存放换算后的传感器数据
 * @return 0 成功，负数表示 SPI 读取失败
 */
static int read_raw(bmi088_t *imu, bmi088_sample_t *sample)
{
	uint8_t raw[6];
	int ret;

	/* ---------- 读取加速度计数据 ----------
	 * 从寄存器 0x12 开始连续读取 6 字节：
	 *   raw[0-1] = X 轴加速度（小端 int16）
	 *   raw[2-3] = Y 轴加速度（小端 int16）
	 *   raw[4-5] = Z 轴加速度（小端 int16）
	 * 转换公式：加速度(g) = 原始值 / 5460
	 */
	ret = spi_read_reg(&imu->accel_spi, BMI088_ACCEL_DATA, raw,
			   sizeof(raw), true);
	if (ret != 0) {
		return ret;
	}

	sample->ax_g = (float)le_i16(&raw[0]) / BMI088_ACCEL_LSB_PER_G;
	sample->ay_g = (float)le_i16(&raw[2]) / BMI088_ACCEL_LSB_PER_G;
	sample->az_g = (float)le_i16(&raw[4]) / BMI088_ACCEL_LSB_PER_G;

	/* ---------- 读取陀螺仪数据 ----------
	 * 从寄存器 0x02 开始连续读取 6 字节：
	 *   raw[0-1] = X 轴角速度（小端 int16）
	 *   raw[2-3] = Y 轴角速度（小端 int16）
	 *   raw[4-5] = Z 轴角速度（小端 int16）
	 * 转换公式：角速度(°/s) = 原始值 / 16.384 - 零偏
	 * 零偏在 bmi088_init() 中通过静止状态校准获得
	 */
	ret = spi_read_reg(&imu->gyro_spi, BMI088_GYRO_DATA, raw,
			   sizeof(raw), false);
	if (ret != 0) {
		return ret;
	}

	sample->gx_dps = (float)le_i16(&raw[0]) / BMI088_GYRO_LSB_PER_DPS -
			 imu->gyro_offset_dps[0];
	sample->gy_dps = (float)le_i16(&raw[2]) / BMI088_GYRO_LSB_PER_DPS -
			 imu->gyro_offset_dps[1];
	sample->gz_dps = (float)le_i16(&raw[4]) / BMI088_GYRO_LSB_PER_DPS -
			 imu->gyro_offset_dps[2];

	return 0;
}

/**
 * @brief 使用互补滤波器更新姿态角（roll/pitch/yaw）
 *
 * 互补滤波器原理：
 *   加速度计可以测量静态倾角（无漂移但高频噪声大），
 *   陀螺仪可以精确测量角速度（短期精度高但积分会漂移）。
 *   互补滤波器将两者的优势结合：
 *
 *     angle = alpha * (angle_prev + gyro_rate * dt) + (1 - alpha) * accel_angle
 *
 *   其中 alpha = 0.985，即 98.5% 信任陀螺仪积分，1.5% 信任加速度计。
 *   - 陀螺仪积分提供短期高频响应（跟踪快速旋转）
 *   - 加速度计提供长期低频校正（消除陀螺仪积分漂移）
 *   - 57.2957795 = 180/π，弧度转角度的换算因子
 *
 * 偏航角（yaw）特殊处理：
 *   由于没有磁力计，yaw 角无法用加速度计校正（加速度计只能测量 roll 和 pitch），
 *   因此 yaw 仅由陀螺仪 Z 轴角速度积分得到，会随时间缓慢漂移。
 *   yaw 角被归一化到 [-180, +180] 范围内。
 *
 * @param imu    BMI088 设备实例，包含上一次的姿态角状态
 * @param sample 本次读取的传感器数据，函数执行后会填充 roll_deg/pitch_deg/yaw_deg
 */
static void update_attitude(bmi088_t *imu, bmi088_sample_t *sample)
{
	const int64_t now = now_us();
	float dt_s = 0.001f;  /* 默认 dt = 1ms（首次调用时使用） */

	/* 计算自上次更新以来的时间间隔 dt（秒）
	 * 首次调用时 last_update_us 为 0，使用默认值 1ms
	 * CLAMP 限制 dt 在 [0.2ms, 20ms] 范围内，防止异常值 */
	if (imu->last_update_us != 0) {
		dt_s = (float)(now - imu->last_update_us) * 1.0e-6f;
		dt_s = CLAMP(dt_s, 0.0002f, 0.02f);
	}
	imu->last_update_us = now;

	/* =================================================================
	 * 轴重映射 —— 适配 PCB 上芯片的实际安装方向
	 *
	 * BMI088 芯片在 PCB 上的安装方位：
	 *   芯片 X 轴 -> 机器人侧向（左右方向）-> 对应机器人的 roll（横滚）轴
	 *   芯片 Y 轴 -> 机器人前后方向       -> 对应机器人的 pitch（俯仰）轴
	 *   芯片 Z 轴 -> 垂直于 PCB 平面       -> 对应机器人的 yaw（偏航）轴
	 *
	 * 因此：
	 *   机器人 roll  角 = atan2(加速度计X, 加速度计Z)，使用陀螺仪Y轴角速度积分
	 *   机器人 pitch 角 = atan2(-加速度计Y, sqrt(X^2+Z^2))，使用陀螺仪X轴角速度积分
	 *
	 * 加速度计计算倾角的几何原理：
	 *   roll  = atan2(ax, az)：在 Y-Z 平面投影的角度
	 *   pitch = atan2(-ay, sqrt(ax^2 + az^2))：使用重力在前向和水平面的分量
	 *   负号是因为芯片 Y 轴正方向与机器人 pitch 正方向定义相反
	 *
	 * 转换因子 57.2957795 = 180.0 / 3.14159265，将弧度转换为角度
	 * ================================================================= */
	const float roll_acc =
		atan2f(sample->ax_g, sample->az_g) * 57.2957795f;
	const float pitch_acc =
		atan2f(-sample->ay_g,
		       sqrtf(sample->ax_g * sample->ax_g +
			     sample->az_g * sample->az_g)) * 57.2957795f;

	/* =================================================================
	 * 互补滤波器核心算法
	 *
	 * 公式：angle = alpha * (angle + gyro * dt) + (1 - alpha) * accel_angle
	 *
	 * alpha = 0.985 意味着：
	 *   - 陀螺仪积分结果占 98.5% 权重（跟踪快速变化，响应性好）
	 *   - 加速度计测量结果占 1.5% 权重（消除长期漂移）
	 *
	 * 这种高 alpha 值的配置适合机器人平衡控制：
	 *   - 需要快速响应的姿态变化（防跌倒）
	 *   - 同时在长时间运行中不会因陀螺仪漂移而失控
	 * ================================================================= */
	const float alpha = 0.97f;

	/* =================================================================
	 * 运行时陀螺仪零偏追踪
	 *
	 * 当机器人近似静止时（三个轴角速度均低于阈值），缓慢更新零偏估计，
	 * 补偿陀螺仪因温度变化产生的零偏漂移。
	 *
	 * 阈值：2°/s（静止时陀螺仪噪声约 0.1~0.5°/s，2°/s 留有裕量）
	 * 学习率：0.001（每秒约更新 0.2% 的零偏，约 5 秒收敛 63%）
	 * 检测窗口：需要连续 200 个样本（约 1 秒）静止才开始更新
	 * ================================================================= */
	const float gyro_mag = sqrtf(sample->gx_dps * sample->gx_dps +
				     sample->gy_dps * sample->gy_dps +
				     sample->gz_dps * sample->gz_dps);
	if (gyro_mag < 2.0f) {
		imu->stationary_count++;
		if (imu->stationary_count > 200) {
			const float lr = 0.001f;
			imu->gyro_runtime_bias_dps[0] += lr * sample->gx_dps;
			imu->gyro_runtime_bias_dps[1] += lr * sample->gy_dps;
			imu->gyro_runtime_bias_dps[2] += lr * sample->gz_dps;
		}
	} else {
		imu->stationary_count = 0;
	}

	/* 应用运行时零偏修正 */
	const float gx_corr = sample->gx_dps - imu->gyro_runtime_bias_dps[0];
	const float gy_corr = sample->gy_dps - imu->gyro_runtime_bias_dps[1];

	/* roll 更新：陀螺仪 Y 轴（chip Y -> 机器人 roll 方向） */
	imu->roll_deg = alpha * (imu->roll_deg + gy_corr * dt_s) +
			(1.0f - alpha) * roll_acc;

	/* pitch 更新：陀螺仪 X 轴（chip X -> 机器人 pitch 方向） */
	imu->pitch_deg = alpha * (imu->pitch_deg + gx_corr * dt_s) +
			 (1.0f - alpha) * pitch_acc;

	/* yaw 更新：仅陀螺仪 Z 轴积分，无加速度计校正（无磁力计）
	 * yaw 会随时间缓慢漂移，但在短时间操作中可接受 */
	imu->yaw_deg += sample->gz_dps * dt_s;

	/* yaw 角归一化到 [-180°, +180°] 范围 */
	while (imu->yaw_deg > 180.0f) {
		imu->yaw_deg -= 360.0f;
	}
	while (imu->yaw_deg < -180.0f) {
		imu->yaw_deg += 360.0f;
	}

	/* 输出结果：
	 * roll 减去静态零位偏置（APP_IMU_ROLL_ZERO_DEG），用于补偿安装角度误差
	 * pitch 减去静态零位偏置（APP_IMU_PITCH_ZERO_DEG），用于补偿安装偏差
	 * yaw 直接输出 */
	sample->roll_deg = imu->roll_deg - APP_IMU_ROLL_ZERO_DEG;
	sample->pitch_deg = imu->pitch_deg - APP_IMU_PITCH_ZERO_DEG;
	sample->yaw_deg = imu->yaw_deg;
}

/**
 * @brief 初始化 BMI088 IMU 传感器
 *
 * 初始化流程：
 *   1. 从设备树获取加速度计和陀螺仪的 SPI 设备规格
 *   2. 检查 SPI 总线是否就绪
 *   3. 对加速度计和陀螺仪执行软复位
 *   4. 读取并校验芯片 ID（加速度计应为 0x1E，陀螺仪应为 0x0F）
 *   5. 配置加速度计：开启电源、设置量程 ±6g、ODR=800Hz
 *   6. 配置陀螺仪：正常模式、量程 ±2000°/s、ODR=1000Hz
 *   7. 陀螺仪零偏校准：采集 300 个样本取平均值作为零偏
 *   8. 用加速度计读数初始化 roll 和 pitch 角
 *
 * @param imu BMI088 设备实例（调用前无需初始化，函数内会 memset 清零）
 * @return 0 成功，负数表示初始化失败
 */
int bmi088_init(bmi088_t *imu)
{
	if (imu == NULL) {
		return -EINVAL;
	}

	/* 清零整个设备结构体 */
	memset(imu, 0, sizeof(*imu));

	/* 从设备树获取 SPI 设备规格（SPI 模式、频率等在 DTS 中配置）
	 * SPI_OP_MODE_MASTER: 主机模式
	 * SPI_WORD_SET(8):    8 位字长 */
	imu->accel_spi = (struct spi_dt_spec)SPI_DT_SPEC_GET(
		BMI088_ACCEL_NODE, SPI_OP_MODE_MASTER | SPI_WORD_SET(8), 0);
	imu->gyro_spi = (struct spi_dt_spec)SPI_DT_SPEC_GET(
		BMI088_GYRO_NODE, SPI_OP_MODE_MASTER | SPI_WORD_SET(8), 0);

	/* 检查两个 SPI 总线是否都已初始化就绪 */
	if (!spi_is_ready_dt(&imu->accel_spi) ||
	    !spi_is_ready_dt(&imu->gyro_spi)) {
		LOG_ERR("BMI088 SPI is not ready");
		return -ENODEV;
	}

	/* 软复位：向软复位寄存器写入 0xB6，将传感器恢复到默认配置
	 * 复位后需等待 50ms 才能进行后续操作（数据手册规定） */
	(void)spi_write_reg(&imu->accel_spi, BMI088_ACCEL_SOFTRESET, 0xb6);
	(void)spi_write_reg(&imu->gyro_spi, BMI088_GYRO_SOFTRESET, 0xb6);
	k_msleep(50);

	/* 读取芯片 ID 并校验，确认 SPI 通信正常且连接的是 BMI088 */
	uint8_t id = 0;
	int ret = spi_read_reg(&imu->accel_spi, BMI088_ACCEL_CHIP_ID, &id, 1,
			       true);
	if (ret != 0) {
		return ret;
	}
	/* 加速度计 ID 应为 0x1E，不匹配时仅警告（不阻断初始化） */
	if (id != BMI088_ACCEL_ID_VALUE) {
		LOG_WRN("unexpected BMI088 accel chip id 0x%02x", id);
	}

	ret = spi_read_reg(&imu->gyro_spi, BMI088_GYRO_CHIP_ID, &id, 1,
			   false);
	if (ret != 0) {
		return ret;
	}
	/* 陀螺仪 ID 应为 0x0F，不匹配时仅警告 */
	if (id != BMI088_GYRO_ID_VALUE) {
		LOG_WRN("unexpected BMI088 gyro chip id 0x%02x", id);
	}

	/* ========== 加速度计配置 ==========
	 * 配置顺序要求：先开启电源，再配置参数（数据手册规定）
	 */
	/* PWR_CTRL = 0x04: 开启加速度计（ACC_ENABLE = 1） */
	(void)spi_write_reg(&imu->accel_spi, BMI088_ACCEL_PWR_CTRL, 0x04);
	k_msleep(5);  /* 等待加速度计电源稳定 */
	/* PWR_CONF = 0x00: 设为 active 模式（非挂起/低功耗） */
	(void)spi_write_reg(&imu->accel_spi, BMI088_ACCEL_PWR_CONF, 0x00);
	k_msleep(5);  /* 等待模式切换完成 */
	/* CONF = 0xA8: ODR=800Hz, BWP=OSR4（带宽=ODR/4=200Hz，过采样4倍） */
	(void)spi_write_reg(&imu->accel_spi, BMI088_ACCEL_CONF, 0xa8);
	/* RANGE = 0x01: 量程 ±6g（灵敏度 5460 LSB/g） */
	(void)spi_write_reg(&imu->accel_spi, BMI088_ACCEL_RANGE, 0x01);

	/* ========== 陀螺仪配置 ========== */
	/* LPM1 = 0x00: 正常功耗模式（非挂起） */
	(void)spi_write_reg(&imu->gyro_spi, BMI088_GYRO_LPM1, 0x00);
	/* RANGE = 0x00: 量程 ±2000°/s（灵敏度 16.384 LSB/°/s） */
	(void)spi_write_reg(&imu->gyro_spi, BMI088_GYRO_RANGE, 0x00);
	/* BANDWIDTH = 0x02: ODR=1000Hz, 带宽=116Hz（滤波器截止频率） */
	(void)spi_write_reg(&imu->gyro_spi, BMI088_GYRO_BANDWIDTH, 0x02);
	k_msleep(20);  /* 等待陀螺仪配置生效 */

	/* ========== 陀螺仪零偏校准 ==========
	 *
	 * 校准原理：陀螺仪在静止状态下，三个轴的角速度输出理论上应为零，
	 * 但实际上由于制造公差和温度影响，会存在一个非零的固定偏移（零偏/bias）。
	 * 如果不补偿这个零偏，积分得到的角度会随时间快速漂移。
	 *
	 * 校准方法：假设传感器在初始化时保持静止，连续采集 300 个样本取平均值，
	 * 作为零偏补偿量，后续每次读取角速度时减去该零偏。
	 *
	 * 300 个样本，每 2ms 采样一次，总校准时间约 600ms。
	 */
	bmi088_sample_t sample;
	float gyro_sum[3] = { 0.0f, 0.0f, 0.0f };
	const int calibration_count = 1000;

	for (int i = 0; i < calibration_count; i++) {
		memset(&sample, 0, sizeof(sample));
		ret = read_raw(imu, &sample);
		if (ret != 0) {
			return ret;
		}

		/* 累加各轴角速度读数（注意此时 read_raw 尚未减去零偏，
		 * 因为 gyro_offset_dps 还是 0） */
		gyro_sum[0] += sample.gx_dps;
		gyro_sum[1] += sample.gy_dps;
		gyro_sum[2] += sample.gz_dps;
		k_msleep(2);  /* 采样间隔 2ms */
	}

	/* 计算平均值作为零偏补偿量 */
	imu->gyro_offset_dps[0] = gyro_sum[0] / calibration_count;
	imu->gyro_offset_dps[1] = gyro_sum[1] / calibration_count;
	imu->gyro_offset_dps[2] = gyro_sum[2] / calibration_count;

	/* ========== 初始姿态估计 ==========
	 * 用加速度计的当前读数初始化 roll 和 pitch 角
	 * 加速度计在静止时可准确测量重力方向，从而得到初始倾角
	 * yaw 初始设为 0°（无磁力计参考，只能从零开始积分）
	 */
	ret = read_raw(imu, &sample);
	if (ret != 0) {
		return ret;
	}

	/* 初始 roll = atan2(ax, az)，转换为角度 */
	imu->roll_deg = atan2f(sample.ax_g, sample.az_g) * 57.2957795f;
	/* 初始 pitch = atan2(-ay, sqrt(ax^2 + az^2))，转换为角度 */
	imu->pitch_deg = atan2f(-sample.ay_g,
				sqrtf(sample.ax_g * sample.ax_g +
				      sample.az_g * sample.az_g)) *
			 57.2957795f;
	imu->yaw_deg = 0.0f;
	/* 记录初始时间戳，供后续互补滤波器计算 dt */
	imu->last_update_us = now_us();
	/* 标记初始化完成，bmi088_update() 可以开始工作 */
	imu->ready = true;

	LOG_INF("BMI088 ready, gyro offset %.3f %.3f %.3f dps",
		(double)imu->gyro_offset_dps[0],
		(double)imu->gyro_offset_dps[1],
		(double)imu->gyro_offset_dps[2]);
	return 0;
}

/**
 * @brief 读取传感器数据并更新姿态角（主循环调用入口）
 *
 * 本函数应在控制循环中周期性调用（典型频率 500Hz~1kHz）。
 * 执行流程：
 *   1. 参数合法性检查（包括 ready 标志，确保已完成初始化和校准）
 *   2. 读取加速度计和陀螺仪原始数据，换算为物理单位并减去零偏
 *   3. 调用互补滤波器更新 roll/pitch/yaw 姿态角
 *
 * @param imu BMI088 设备实例
 * @param out 输出结构体，包含原始传感器数据和计算后的姿态角
 *            - ax_g/ay_g/az_g: 加速度（g）
 *            - gx_dps/gy_dps/gz_dps: 角速度（°/s，已校准）
 *            - roll_deg/pitch_deg/yaw_deg: 姿态角（°）
 * @return 0 成功，负数表示读取失败或参数无效
 */
int bmi088_update(bmi088_t *imu, bmi088_sample_t *out)
{
	if (imu == NULL || out == NULL || !imu->ready) {
		return -EINVAL;
	}

	/* 读取原始数据并转换为物理单位（含零偏校准） */
	int ret = read_raw(imu, out);
	if (ret != 0) {
		return ret;
	}

	/* 互补滤波器更新姿态角 */
	update_attitude(imu, out);
	return 0;
}

/**
 * @brief 检查 BMI088 是否已完成初始化并可正常使用
 *
 * @param imu BMI088 设备实例
 * @return true 已就绪，false 未初始化或指针为 NULL
 */
bool bmi088_is_ready(const bmi088_t *imu)
{
	return imu != NULL && imu->ready;
}
```

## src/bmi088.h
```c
/**
 * @file bmi088.h
 * @brief BMI088 六轴 IMU 传感器驱动接口
 *
 * 本文件定义了 Bosch BMI088 六轴惯性测量单元（IMU）的驱动接口。
 * BMI088 包含一个三轴加速度计和一个三轴陀螺仪，通过 SPI 接口通信。
 *
 * 在本项目中的作用：
 *   - 提供机器人的姿态角（俯仰、横滚、偏航）
 *   - 提供角速度用于平衡控制的阻尼反馈
 *   - 提供加速度数据用于姿态估计
 *
 * 硬件连接：
 *   - 加速度计和陀螺仪各有独立的 SPI 片选信号（CS）
 *   - 共用同一条 SPI 总线，但作为两个独立的 SPI 设备操作
 *
 * 姿态估计：
 *   - 使用互补滤波器融合加速度计和陀螺仪数据
 *   - 加速度计提供静态姿态参考（低频，受振动影响大）
 *   - 陀螺仪提供动态角速度（高频，存在漂移）
 *   - 互补滤波器结合两者优点，输出稳定的姿态角
 */

#pragma once

#include <stdbool.h>

#include <zephyr/device.h>
#include <zephyr/drivers/spi.h>

/**
 * @brief BMI088 采样数据结构体
 *
 * 包含一次完整的 IMU 采样结果：原始加速度、角速度和姿态角。
 * 由 bmi088_update() 填充。
 */
typedef struct {
	/* 三轴加速度（加速度计原始数据换算后） */
	float ax_g; /**< X 轴加速度，单位：重力加速度 g（1g ≈ 9.81 m/s^2） */
	float ay_g; /**< Y 轴加速度，单位：g */
	float az_g; /**< Z 轴加速度，单位：g（静止时约为 1g，方向朝上） */

	/* 三轴角速度（陀螺仪原始数据换算后） */
	float gx_dps; /**< X 轴（横滚轴）角速度，单位：度/秒（deg/s） */
	float gy_dps; /**< Y 轴（俯仰轴）角速度，单位：度/秒（deg/s） */
	float gz_dps; /**< Z 轴（偏航轴）角速度，单位：度/秒（deg/s） */

	/* 姿态角（互补滤波器融合后） */
	float roll_deg;  /**< 横滚角，单位：度（deg），右倾为正 */
	float pitch_deg; /**< 俯仰角，单位：度（deg），前倾为正 */
	float yaw_deg;   /**< 偏航角，单位：度（deg），仅陀螺仪积分，会漂移 */
} bmi088_sample_t;

/**
 * @brief BMI088 驱动实例结构体
 *
 * 包含 SPI 设备句柄、校准偏移、姿态估计状态等。
 * 由 bmi088_init() 初始化，bmi088_update() 更新。
 */
typedef struct {
	/* SPI 设备配置 */
	struct spi_dt_spec accel_spi; /**< 加速度计的 SPI 设备规格（含片选引脚、时钟频率等） */
	struct spi_dt_spec gyro_spi;  /**< 陀螺仪的 SPI 设备规格（含片选引脚、时钟频率等） */

	/* 陀螺仪零偏校准 */
	float gyro_offset_dps[3]; /**< 陀螺仪三轴零偏偏移，单位：度/秒（deg/s） */
	/* 陀螺仪在静止时读数不为零，此偏移量在初始化时校准并减去 */

	/* 运行时陀螺仪零偏追踪（对抗温度漂移） */
	float gyro_runtime_bias_dps[3]; /**< 运行时零偏追踪值，单位：度/秒 */
	int stationary_count;            /**< 静止检测计数器 */

	/* 姿态角估计状态（互补滤波器输出） */
	float roll_deg;  /**< 当前横滚角估计值，单位：度（deg） */
	float pitch_deg; /**< 当前俯仰角估计值，单位：度（deg） */
	float yaw_deg;   /**< 当前偏航角估计值，单位：度（deg）（仅陀螺仪积分，会缓慢漂移） */

	int64_t last_update_us; /**< 上次更新的时间戳，单位：微秒（us），用于计算 dt */
	bool ready;             /**< 驱动是否就绪（true = 初始化成功，可读取数据） */
} bmi088_t;

/**
 * @brief 初始化 BMI088 IMU 传感器
 * @param[out] imu 指向驱动实例结构体的指针
 * @return 0 成功，非零失败
 *
 * 初始化过程包括：
 *   1. 配置 SPI 通信参数
 *   2. 复位加速度计和陀螺仪芯片
 *   3. 配置量程和输出数据率（ODR）
 *   4. 执行陀螺仪零偏校准（需保持静止）
 *   5. 初始化姿态角为零
 */
int bmi088_init(bmi088_t *imu);

/**
 * @brief 更新 BMI088 采样数据（读取传感器并更新姿态）
 * @param[in,out] imu 驱动实例（更新内部姿态状态）
 * @param[out]    out 采样数据输出（加速度、角速度、姿态角）
 * @return 0 成功，非零失败
 *
 * 每次调用：
 *   1. 通过 SPI 读取加速度计和陀螺仪的原始数据
 *   2. 减去零偏偏移，换算为物理单位
 *   3. 使用互补滤波器更新姿态角
 *   4. 将结果写入 out 结构体
 *
 * 典型调用频率：100~1000 Hz（取决于 BMI088 的 ODR 配置）。
 */
int bmi088_update(bmi088_t *imu, bmi088_sample_t *out);

/**
 * @brief 检查 IMU 驱动是否就绪
 * @param[in] imu 指向驱动实例的指针
 * @return true = 已初始化且可正常读取，false = 未初始化或故障
 */
bool bmi088_is_ready(const bmi088_t *imu);
```

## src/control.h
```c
#pragma once
/**
 * @file control.h
 * @brief 机器人控制系统接口（LQR 控制器路径）
 *
 * 定义控制系统的状态结构体和使能/状态查询 API。
 * 实际平衡算法由 ascento_balance.c 的 LQR 控制器完成，
 * 本文件仅提供状态管理和发布接口。
 */

#include <stdbool.h>
#include <stdint.h>

#include "bmi088.h"
#include "dji_m3508.h"

/**
 * @brief 机器人运动方向枚举
 *
 * 定义机器人整体运动意图，由上层（如遥控器、自主导航）设定。
 */
typedef enum {
	ROBOT_FORWARD = 0, /**< 前进 */
	ROBOT_BACK = 1,    /**< 后退 */
	ROBOT_RIGHT = 2,   /**< 右转 */
	ROBOT_LEFT = 3,    /**< 左转 */
	ROBOT_STOP = 4,    /**< 停止 */
	ROBOT_JUMP = 5,    /**< 跳跃 */
} robot_motion_t;

/**
 * @brief 控制输出结构体
 *
 * 每个控制周期由控制器填充，包含发送给底层电机驱动的指令。
 */
typedef struct {
	bool wheels_enabled;  /**< 轮子是否使能（false 时轮子电流为零，自由转动） */
	bool joints_enabled;  /**< 关节是否使能（false 时关节电机断电） */
	int16_t left_wheel_current;  /**< 左轮目标电流，单位：毫安（mA），正值为前进方向 */
	int16_t right_wheel_current; /**< 右轮目标电流，单位：毫安（mA），正值为前进方向 */
	float left_joint_position_rad;  /**< 左腿关节目标角度，单位：弧度（rad） */
	float right_joint_position_rad; /**< 右腿关节目标角度，单位：弧度（rad） */
	float joint_velocity_limit_rad_s; /**< 关节角速度限幅，单位：弧度/秒（rad/s） */
} control_output_t;

/**
 * @brief 控制状态结构体
 *
 * 包含控制系统的全部运行时状态，用于调试、遥测和状态监控。
 * 可通过 control_get_status() 获取。
 */
typedef struct {
	bool enable_request;  /**< 控制系统使能请求（true = 已使能） */
	bool wheels_enabled;  /**< 轮子当前是否已使能（经故障保护后的实际状态） */
	bool faulted;         /**< 是否处于故障状态（如倾角过大触发保护） */
	int height;           /**< 当前腿部高度档位 */
	float joy_x;          /**< 摇杆 X 轴输入，范围 -1.0 ~ +1.0 */
	float joy_y;          /**< 摇杆 Y 轴输入，范围 -1.0 ~ +1.0 */
	robot_motion_t motion; /**< 当前运动模式 */
	float pitch_deg;      /**< 机体俯仰角，单位：度（deg），正值为前倾 */
	float pitch_rate_dps; /**< 机体俯仰角速度，单位：度/秒（deg/s） */
	float roll_deg;       /**< 机体横滚角，单位：度（deg） */
	float yaw_deg;        /**< 机体偏航角，单位：度（deg） */
	float distance_rad;   /**< 累计行进距离（轮子编码器积分），单位：弧度（rad） */
	float speed_rad_s;    /**< 轮子平均角速度，单位：弧度/秒（rad/s） */
	float lqr_output;     /**< LQR 平衡控制器输出（调试用） */
	float yaw_output;     /**< 偏航控制器输出（调试用） */
	float left_joint_position_rad;  /**< 左腿关节当前角度，单位：弧度（rad） */
	float right_joint_position_rad; /**< 右腿关节当前角度，单位：弧度（rad） */
	int16_t left_wheel_current;  /**< 左轮当前电流，单位：毫安（mA） */
	int16_t right_wheel_current; /**< 右轮当前电流，单位：毫安（mA） */
	int jump_phase;       /**< 跳跃阶段（0=未跳跃，1=蹲下，2=起跳，3=落地等） */
} control_status_t;

/**
 * @brief 初始化控制系统
 *
 * 初始化内部状态、控制器参数、电机通信等。应在系统启动时调用一次。
 */
void control_init(void);

/**
 * @brief 设置控制系统使能/禁用
 * @param enable true = 使能（电机上电），false = 禁用（电机断电）
 */
void control_set_enable(bool enable);

/**
 * @brief 停止当前运动
 *
 * 将运动模式重置为 ROBOT_STOP，停止前进和转向。
 */
void control_stop_motion(void);

/**
 * @brief 获取控制系统使能请求状态
 * @return true = 已请求使能，false = 未使能
 */
bool control_get_enable_request(void);

/**
 * @brief 获取控制系统的当前状态快照
 * @param[out] status 指向状态结构体的指针，函数将填充当前状态数据
 */
void control_get_status(control_status_t *status);

/**
 * @brief 发布控制状态（通过通信接口发送给上位机）
 * @param[in] status 指向要发布的状态结构体
 */
void control_publish_status(const control_status_t *status);
```

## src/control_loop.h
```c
#pragma once
/**
 * @file control_loop.h
 * @brief 200Hz 平衡控制线程接口
 *
 * 封装实时平衡控制线程的创建和启动。
 * 控制线程以 200Hz 固定频率运行，执行 IMU 读取、状态估计、
 * 平衡控制算法（Ascento LQR 或 PID）以及电机指令下发。
 */

#include "bmi088.h"
#include "dji_m3508.h"
#include "dm4340.h"

/**
 * @brief 最近一次 IMU 采样数据的缓存副本
 *
 * 由控制线程写入，主线程读取（用于周期性日志输出）。
 * 由于只有单个写入者和读取者，且数据可容忍一个采样周期的延迟，
 * 因此无需加锁。
 */
extern bmi088_sample_t last_imu_sample;

/**
 * @brief 启动 200Hz 平衡控制线程
 *
 * 内部完成以下操作：
 *   1. 初始化 PID 控制器状态
 *   2. 初始化 Ascento LQR 控制器（条件编译）
 *   3. 加载运行时参数（NVS）
 *   4. 创建高优先级控制线程（K_PRIO_PREEMPT(2)）
 *
 * @param dji_bus  DJI M3508 轮毂电机总线指针
 * @param dm_bus   DM4340 关节电机总线指针
 * @param imu      BMI088 IMU 实例指针
 */
void control_loop_start(dji_m3508_bus_t *dji_bus, dm4340_bus_t *dm_bus,
			bmi088_t *imu);
```
